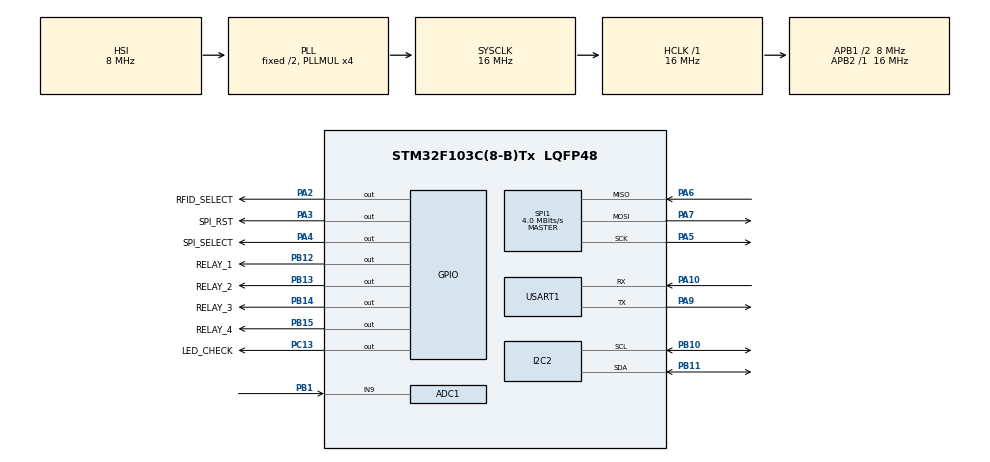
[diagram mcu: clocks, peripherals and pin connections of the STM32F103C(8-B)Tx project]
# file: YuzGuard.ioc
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ADC1.Channel-0\#ChannelRegularConversion=ADC_CHANNEL_9
ADC1.ContinuousConvMode=ENABLE
ADC1.NbrOfConversionFlag=1
ADC1.Rank-0\#ChannelRegularConversion=1
ADC1.SamplingTime-0\#ChannelRegularConversion=ADC_SAMPLETIME_1CYCLE_5
ADC1.master=1
I2C2.I2C_Mode=I2C_Fast
Mcu.Family=STM32F1
Mcu.Name=STM32F103C(8-B)Tx
Mcu.Package=LQFP48
NVIC.PriorityGroup=NVIC_PRIORITYGROUP_4
PA10.Mode=Asynchronous
PA10.Signal=USART1_RX
PA13.Mode=Serial_Wire
PA13.Signal=SYS_JTMS-SWDIO
PA14.Mode=Serial_Wire
PA14.Signal=SYS_JTCK-SWCLK
PA2.GPIO_Label=RFID_SELECT
PA2.GPIO_Speed=GPIO_SPEED_FREQ_HIGH
PA2.Signal=GPIO_Output
PA3.GPIO_Label=SPI_RST
PA3.GPIO_Speed=GPIO_SPEED_FREQ_HIGH
PA3.Signal=GPIO_Output
PA4.GPIO_Label=SPI_SELECT
PA4.GPIO_Speed=GPIO_SPEED_FREQ_HIGH
PA4.Signal=GPIO_Output
PA5.Mode=Full_Duplex_Master
PA5.Signal=SPI1_SCK
PA6.Mode=Full_Duplex_Master
PA6.Signal=SPI1_MISO
PA7.Mode=Full_Duplex_Master
PA7.Signal=SPI1_MOSI
PA9.Mode=Asynchronous
PA9.Signal=USART1_TX
PB1.Signal=ADCx_IN9
PB10.Mode=I2C
PB10.Signal=I2C2_SCL
PB11.Mode=I2C
PB11.Signal=I2C2_SDA
PB12.GPIO_Label=RELAY_1
PB12.GPIO_ModeDefaultOutputPP=GPIO_MODE_OUTPUT_PP
PB12.GPIO_PuPd=GPIO_PULLUP
PB12.GPIO_Speed=GPIO_SPEED_FREQ_MEDIUM
PB12.PinState=GPIO_PIN_RESET
PB12.Signal=GPIO_Output
PB13.GPIO_Label=RELAY_2
PB13.GPIO_ModeDefaultOutputPP=GPIO_MODE_OUTPUT_PP
PB13.GPIO_PuPd=GPIO_PULLUP
PB13.GPIO_Speed=GPIO_SPEED_FREQ_MEDIUM
PB13.PinState=GPIO_PIN_RESET
PB13.Signal=GPIO_Output
PB14.GPIO_Label=RELAY_3
PB14.GPIO_PuPd=GPIO_PULLUP
PB14.GPIO_Speed=GPIO_SPEED_FREQ_MEDIUM
PB14.Signal=GPIO_Output
PB15.GPIO_Label=RELAY_4
PB15.GPIO_PuPd=GPIO_PULLUP
PB15.GPIO_Speed=GPIO_SPEED_FREQ_LOW
PB15.Signal=GPIO_Output
PC13-TAMPER-RTC.GPIO_Label=LED_CHECK
PC13-TAMPER-RTC.GPIO_Speed=GPIO_SPEED_FREQ_LOW
PC13-TAMPER-RTC.PinState=GPIO_PIN_SET
PC13-TAMPER-RTC.Signal=GPIO_Output
PC14-OSC32_IN.Mode=LSE-External-Oscillator
PC14-OSC32_IN.Signal=RCC_OSC32_IN
PC15-OSC32_OUT.Mode=LSE-External-Oscillator
PC15-OSC32_OUT.Signal=RCC_OSC32_OUT
PD0-OSC_IN.Mode=HSE-External-Oscillator
PD0-OSC_IN.Signal=RCC_OSC_IN
PD1-OSC_OUT.Mode=HSE-External-Oscillator
PD1-OSC_OUT.Signal=RCC_OSC_OUT
ProjectManager.HeapSize=0x200
ProjectManager.StackSize=0x400
ProjectManager.TargetToolchain=STM32CubeIDE
RCC.AHBFreq_Value=16000000
RCC.APB1CLKDivider=RCC_HCLK_DIV2
RCC.APB1Freq_Value=8000000
RCC.APB1TimFreq_Value=16000000
RCC.APB2Freq_Value=16000000
RCC.APB2TimFreq_Value=16000000
RCC.HCLKFreq_Value=16000000
RCC.PLLMUL=RCC_PLL_MUL4
RCC.RTCClockSelection=RCC_RTCCLKSOURCE_LSE
RCC.SYSCLKFreq_VALUE=16000000
RCC.SYSCLKSource=RCC_SYSCLKSOURCE_PLLCLK
RCC.USBFreq_Value=16000000
SH.ADCx_IN9.0=ADC1_IN9,IN9
SPI1.BaudRatePrescaler=SPI_BAUDRATEPRESCALER_4
SPI1.CalculateBaudRate=4.0 MBits/s
SPI1.Direction=SPI_DIRECTION_2LINES
SPI1.Mode=SPI_MODE_MASTER
SPI1.VirtualType=VM_MASTER
USART1.VirtualMode=VM_ASYNC
VP_RTC_VS_RTC_Activate.Mode=RTC_Enabled
board=custom

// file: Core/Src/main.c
/* USER CODE BEGIN Header */
/**
  ******************************************************************************
  * @file           : main.c
  * @brief          : Main program body
  ******************************************************************************
  * @attention
  *
  * Copyright (c) 2023 STMicroelectronics.
  * All rights reserved.
  *
  * This software is licensed under terms that can be found in the LICENSE file
  * in the root directory of this software component.
  * If no LICENSE file comes with this software, it is provided AS-IS.
  *
  ******************************************************************************
  */
/* USER CODE END Header */
#include "main.h"

/* USER CODE BEGIN Includes */
//#include ""
#include <stdio.h>
#include <string.h>
#include <stdbool.h>
//------- user added libraries
#include "cJSON.h"
#include "AHT20.h"

/* USER CODE END Includes */

ADC_HandleTypeDef hadc1;

I2C_HandleTypeDef hi2c2;

RTC_HandleTypeDef hrtc;

SPI_HandleTypeDef hspi1;

UART_HandleTypeDef huart1;

void SystemClock_Config(void);
static void MX_GPIO_Init(void);
static void MX_SPI1_Init(void);
static void MX_USART1_UART_Init(void);
static void MX_ADC1_Init(void);
static void MX_I2C2_Init(void);
static void MX_RTC_Init(void);

int main(void)
{

  /* MCU Configuration--------------------------------------------------------*/

  /* Reset of all peripherals, Initializes the Flash interface and the Systick. */
  HAL_Init();

  /* Configure the system clock */
  SystemClock_Config();

  /* Initialize all configured peripherals */
  MX_GPIO_Init();
  MX_SPI1_Init();
  MX_USART1_UART_Init();
  MX_ADC1_Init();
  MX_I2C2_Init();
  MX_RTC_Init();
  /* USER CODE BEGIN 2 */
  HAL_GPIO_WritePin(LED_CHECK_GPIO_Port, LED_CHECK_Pin, 1);
  HAL_GPIO_WritePin(RELAY_1_GPIO_Port, RELAY_1_Pin, 0);
  HAL_GPIO_WritePin(RELAY_2_GPIO_Port, RELAY_2_Pin, 0);
  HAL_GPIO_WritePin(RELAY_3_GPIO_Port, RELAY_3_Pin, 0);
  HAL_GPIO_WritePin(RELAY_4_GPIO_Port, RELAY_4_Pin, 0);
  /* USER CODE END 2 */

  /* Infinite loop */
  /* USER CODE BEGIN WHILE */
  while (1)
  {

	  HAL_GPIO_TogglePin(LED_CHECK_GPIO_Port, LED_CHECK_Pin);
	  HAL_Delay(1000);
    /* USER CODE END WHILE */

  }
}

void SystemClock_Config(void)
{
  RCC_OscInitTypeDef RCC_OscInitStruct = {0};
  RCC_ClkInitTypeDef RCC_ClkInitStruct = {0};
  RCC_PeriphCLKInitTypeDef PeriphClkInit = {0};

  /** Initializes the RCC Oscillators according to the specified parameters
  * in the RCC_OscInitTypeDef structure.
  */
  RCC_OscInitStruct.OscillatorType = RCC_OSCILLATORTYPE_HSI|RCC_OSCILLATORTYPE_LSE;
  RCC_OscInitStruct.LSEState = RCC_LSE_ON;
  RCC_OscInitStruct.HSIState = RCC_HSI_ON;
  RCC_OscInitStruct.HSICalibrationValue = RCC_HSICALIBRATION_DEFAULT;
  RCC_OscInitStruct.PLL.PLLState = RCC_PLL_ON;
  RCC_OscInitStruct.PLL.PLLSource = RCC_PLLSOURCE_HSI_DIV2;
  RCC_OscInitStruct.PLL.PLLMUL = RCC_PLL_MUL4;
  if (HAL_RCC_OscConfig(&RCC_OscInitStruct) != HAL_OK)
  {
    Error_Handler();
  }

  /** Initializes the CPU, AHB and APB buses clocks
  */
  RCC_ClkInitStruct.ClockType = RCC_CLOCKTYPE_HCLK|RCC_CLOCKTYPE_SYSCLK
                              |RCC_CLOCKTYPE_PCLK1|RCC_CLOCKTYPE_PCLK2;
  RCC_ClkInitStruct.SYSCLKSource = RCC_SYSCLKSOURCE_PLLCLK;
  RCC_ClkInitStruct.AHBCLKDivider = RCC_SYSCLK_DIV1;
  RCC_ClkInitStruct.APB1CLKDivider = RCC_HCLK_DIV2;
  RCC_ClkInitStruct.APB2CLKDivider = RCC_HCLK_DIV1;

  if (HAL_RCC_ClockConfig(&RCC_ClkInitStruct, FLASH_LATENCY_0) != HAL_OK)
  {
    Error_Handler();
  }
  PeriphClkInit.PeriphClockSelection = RCC_PERIPHCLK_RTC|RCC_PERIPHCLK_ADC;
  PeriphClkInit.RTCClockSelection = RCC_RTCCLKSOURCE_LSE;
  PeriphClkInit.AdcClockSelection = RCC_ADCPCLK2_DIV2;
  if (HAL_RCCEx_PeriphCLKConfig(&PeriphClkInit) != HAL_OK)
  {
    Error_Handler();
  }
}

static void MX_ADC1_Init(void)
{

  ADC_ChannelConfTypeDef sConfig = {0};

  /** Common config
  */
  hadc1.Instance = ADC1;
  hadc1.Init.ScanConvMode = ADC_SCAN_DISABLE;
  hadc1.Init.ContinuousConvMode = ENABLE;
  hadc1.Init.DiscontinuousConvMode = DISABLE;
  hadc1.Init.ExternalTrigConv = ADC_SOFTWARE_START;
  hadc1.Init.DataAlign = ADC_DATAALIGN_RIGHT;
  hadc1.Init.NbrOfConversion = 1;
  if (HAL_ADC_Init(&hadc1) != HAL_OK)
  {
    Error_Handler();
  }

  /** Configure Regular Channel
  */
  sConfig.Channel = ADC_CHANNEL_9;
  sConfig.Rank = ADC_REGULAR_RANK_1;
  sConfig.SamplingTime = ADC_SAMPLETIME_1CYCLE_5;
  if (HAL_ADC_ConfigChannel(&hadc1, &sConfig) != HAL_OK)
  {
    Error_Handler();
  }

}

static void MX_I2C2_Init(void)
{

  hi2c2.Instance = I2C2;
  hi2c2.Init.ClockSpeed = 400000;
  hi2c2.Init.DutyCycle = I2C_DUTYCYCLE_2;
  hi2c2.Init.OwnAddress1 = 0;
  hi2c2.Init.AddressingMode = I2C_ADDRESSINGMODE_7BIT;
  hi2c2.Init.DualAddressMode = I2C_DUALADDRESS_DISABLE;
  hi2c2.Init.OwnAddress2 = 0;
  hi2c2.Init.GeneralCallMode = I2C_GENERALCALL_DISABLE;
  hi2c2.Init.NoStretchMode = I2C_NOSTRETCH_DISABLE;
  if (HAL_I2C_Init(&hi2c2) != HAL_OK)
  {
    Error_Handler();
  }

}

static void MX_RTC_Init(void)
{

  /** Initialize RTC Only
  */
  hrtc.Instance = RTC;
  hrtc.Init.AsynchPrediv = RTC_AUTO_1_SECOND;
  hrtc.Init.OutPut = RTC_OUTPUTSOURCE_ALARM;
  if (HAL_RTC_Init(&hrtc) != HAL_OK)
  {
    Error_Handler();
  }

}

static void MX_SPI1_Init(void)
{

  /* SPI1 parameter configuration*/
  hspi1.Instance = SPI1;
  hspi1.Init.Mode = SPI_MODE_MASTER;
  hspi1.Init.Direction = SPI_DIRECTION_2LINES;
  hspi1.Init.DataSize = SPI_DATASIZE_8BIT;
  hspi1.Init.CLKPolarity = SPI_POLARITY_LOW;
  hspi1.Init.CLKPhase = SPI_PHASE_1EDGE;
  hspi1.Init.NSS = SPI_NSS_SOFT;
  hspi1.Init.BaudRatePrescaler = SPI_BAUDRATEPRESCALER_4;
  hspi1.Init.FirstBit = SPI_FIRSTBIT_MSB;
  hspi1.Init.TIMode = SPI_TIMODE_DISABLE;
  hspi1.Init.CRCCalculation = SPI_CRCCALCULATION_DISABLE;
  hspi1.Init.CRCPolynomial = 10;
  if (HAL_SPI_Init(&hspi1) != HAL_OK)
  {
    Error_Handler();
  }

}

static void MX_USART1_UART_Init(void)
{

  huart1.Instance = USART1;
  huart1.Init.BaudRate = 115200;
  huart1.Init.WordLength = UART_WORDLENGTH_8B;
  huart1.Init.StopBits = UART_STOPBITS_1;
  huart1.Init.Parity = UART_PARITY_NONE;
  huart1.Init.Mode = UART_MODE_TX_RX;
  huart1.Init.HwFlowCtl = UART_HWCONTROL_NONE;
  huart1.Init.OverSampling = UART_OVERSAMPLING_16;
  if (HAL_UART_Init(&huart1) != HAL_OK)
  {
    Error_Handler();
  }

}

static void MX_GPIO_Init(void)
{
  GPIO_InitTypeDef GPIO_InitStruct = {0};

  /* GPIO Ports Clock Enable */
  __HAL_RCC_GPIOC_CLK_ENABLE();
  __HAL_RCC_GPIOD_CLK_ENABLE();
  __HAL_RCC_GPIOA_CLK_ENABLE();
  __HAL_RCC_GPIOB_CLK_ENABLE();

  /*Configure GPIO pin Output Level */
  HAL_GPIO_WritePin(LED_CHECK_GPIO_Port, LED_CHECK_Pin, GPIO_PIN_SET);

  /*Configure GPIO pin Output Level */
  HAL_GPIO_WritePin(GPIOA, RFID_SELECT_Pin|SPI_RST_Pin|SPI_SELECT_Pin, GPIO_PIN_RESET);

  /*Configure GPIO pin Output Level */
  HAL_GPIO_WritePin(GPIOB, RELAY_1_Pin|RELAY_2_Pin|RELAY_3_Pin|RELAY_4_Pin, GPIO_PIN_RESET);

  /*Configure GPIO pin : LED_CHECK_Pin */
  GPIO_InitStruct.Pin = LED_CHECK_Pin;
  GPIO_InitStruct.Mode = GPIO_MODE_OUTPUT_PP;
  GPIO_InitStruct.Pull = GPIO_NOPULL;
  GPIO_InitStruct.Speed = GPIO_SPEED_FREQ_LOW;
  HAL_GPIO_Init(LED_CHECK_GPIO_Port, &GPIO_InitStruct);

  /*Configure GPIO pins : RFID_SELECT_Pin SPI_RST_Pin SPI_SELECT_Pin */
  GPIO_InitStruct.Pin = RFID_SELECT_Pin|SPI_RST_Pin|SPI_SELECT_Pin;
  GPIO_InitStruct.Mode = GPIO_MODE_OUTPUT_PP;
  GPIO_InitStruct.Pull = GPIO_NOPULL;
  GPIO_InitStruct.Speed = GPIO_SPEED_FREQ_HIGH;
  HAL_GPIO_Init(GPIOA, &GPIO_InitStruct);

  /*Configure GPIO pins : RELAY_1_Pin RELAY_2_Pin RELAY_3_Pin */
  GPIO_InitStruct.Pin = RELAY_1_Pin|RELAY_2_Pin|RELAY_3_Pin;
  GPIO_InitStruct.Mode = GPIO_MODE_OUTPUT_PP;
  GPIO_InitStruct.Pull = GPIO_PULLUP;
  GPIO_InitStruct.Speed = GPIO_SPEED_FREQ_MEDIUM;
  HAL_GPIO_Init(GPIOB, &GPIO_InitStruct);

  /*Configure GPIO pin : RELAY_4_Pin */
  GPIO_InitStruct.Pin = RELAY_4_Pin;
  GPIO_InitStruct.Mode = GPIO_MODE_OUTPUT_PP;
  GPIO_InitStruct.Pull = GPIO_PULLUP;
  GPIO_InitStruct.Speed = GPIO_SPEED_FREQ_LOW;
  HAL_GPIO_Init(RELAY_4_GPIO_Port, &GPIO_InitStruct);

}

void Error_Handler(void)
{
  __disable_irq();
  while (1)
  {
  }
}
